# LPC15xx register map
File version: 0.7
CPU: CM3 r2p1, little endian, no MPU, no FPU, 3 interrupt priority bits
Registers are 32-bit, read-write, reset 0x0 unless marked. A register's access mark holds for its fields unless they carry their own. Offsets are from the block's base; [hi:lo] are bit positions; lines under a group give offsets from that group; {n}, {i} and the like mark numbered series.

## GINT0 — Group interrupt 0/1 (GINT0/1)
Base 0x400A8000
Same registers: GINT1 0x400AC000
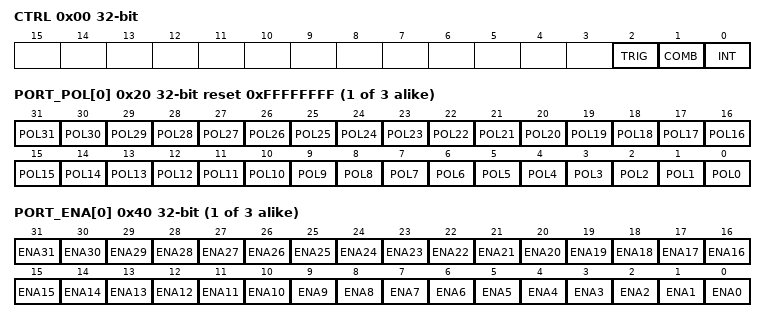
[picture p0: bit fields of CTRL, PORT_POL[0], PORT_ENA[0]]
0x00 CTRL — GPIO grouped interrupt control register
  [2] TRIG — Group interrupt trigger
    0=EDGE_TRIGGERED; 1=LEVEL_TRIGGERED
  [1] COMB — Combine enabled inputs for group interrupt
    0=OR_FUNCTIONALITY_A_ (OR functionality: A grouped interrupt is generated when any one of the enabled inputs is active (based on its programmed polarity).); 1=AND_FUNCTIONALITY_A (AND functionality: An interrupt is generated when all enabled bits are active (based on their programmed polarity).)
  [0] INT — Group interrupt status. This bit is cleared by writing a one to it. Writing zero has no effect.
    0=NO_INTERRUPT_REQUEST (No interrupt request is pending.); 1=INTERRUPT_REQUEST_IS (Interrupt request is active.)
{0x20+4i} PORT_POL[{i}] (i=0..2) reset 0xFFFFFFFF — GPIO grouped interrupt port 0 polarity register
  [n] POL{n} (n=0..31) — Configure pin polarity of port m pins for group interrupt. Bit n corresponds to pin PIOm_n of port m. 0 = the pin is active LOW. If the level on this pin is LOW, the pin contributes to the group interrupt. 1 = the pin is active HIGH. If the level on this pin is HIGH, the pin contributes to the group interrupt.
{0x40+4i} PORT_ENA[{i}] (i=0..2) — GPIO grouped interrupt port 0 enable register
  [n] ENA{n} (n=0..31) — Enable port 0 pin for group interrupt. Bit n corresponds to pin Pm_n of port m. 0 = the port 0 pin is disabled and does not contribute to the grouped interrupt. 1 = the port 0 pin is enabled and contributes to the grouped interrupt.

## RIT — Repetitive Interrupt Timer (RIT)
Base 0x400B4000
0x00 COMPVAL reset 0xFFFFFFFF — Compare value LSB register. Holds the 32 LSBs of the compare value.
  [31:0] RICOMP — Compare register. Holds the 32 LSBs of the compare value which is compared to the counter.
0x04 MASK — Mask LSB register. This register holds the 32 LSB s of the mask value. A 1 written to any bit will force a compare on the corresponding bit of the counter and compare register.
  [31:0] RIMASK — Mask register. This register holds the 32 LSBs of the mask value. A one written to any bit overrides the result of the comparison for the corresponding bit of the counter and compare register (causes the comparison of the register bits to be always true).
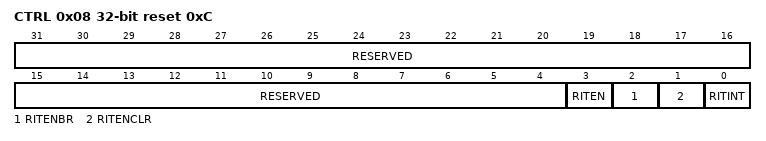
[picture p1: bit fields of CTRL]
0x08 CTRL reset 0xC — Control register.
  [31:4] RESERVED — Reserved, user software should not write ones to reserved bits. The value read from a reserved bit is not defined.
  [3] RITEN — Timer enable.
    1=TIMER_ENABLED (Timer enabled. This can be overruled by a debug halt if enabled in bit 2.); 0=TIMER_DISABLED
  [2] RITENBR — Timer enable for debug
    1=THE_TIMER_IS_HALTED (The timer is halted when the processor is halted for debugging.); 0=DEBUG_HAS_NO_EFFECT (Debug has no effect on the timer operation.)
  [1] RITENCLR — Timer enable clear
    1=THE_TIMER_WILL_BE_CL (The timer will be cleared to 0 whenever the counter value equals the masked compare value specified by the contents of COMPVAL/COMPVAL_H and MASK/MASK_H registers. This will occur on the same clock that sets the interrupt flag.); 0=THE_TIMER_WILL_NOT_B (The timer will not be cleared to 0.)
  [0] RITINT — Interrupt flag
    1=THIS_BIT_IS_SET_TO_1 (This bit is set to 1 by hardware whenever the counter value equals the masked compare value specified by the contents of RICOMPVAL and RIMASK registers. Writing a 1 to this bit will clear it to 0. Writing a 0 has no effect.); 0=THE_COUNTER_VALUE_DO (The counter value does not equal the masked compare value.)
0x0C COUNTER — Counter LSB register. 32 LSBs of the counter.
  [31:0] RICOUNTER — 32 LSBs of the up counter. Counts continuously unless RITEN bit in CTRL register is cleared or debug mode is entered (if enabled by the RITNEBR bit in RICTRL). Can be loaded to any value in software.
0x10 COMPVAL_H reset 0xFFFF — Compare value MSB register. Holds the 16 MSBs of the compare value.
  [15:0] RICOMP — Compare value MSB register. Holds the 16 MSBs of the compare value which is compared to the counter.
0x14 MASK_H — Mask MSB register. This register holds the 16 MSBs of the mask value. A 1 written to any bit will force a compare on the corresponding bit of the counter and compare register.
  [15:0] RIMASK — Mask register. This register holds the 16 MSBs of the mask value. A one written to any bit overrides the result of the comparison for the corresponding bit of the counter and compare register (causes the comparison of the register bits to be always true).
0x1C COUNTER_H — Counter MSB register. 16 MSBs of the counter.
  [15:0] RICOUNTER — 16 LSBs of the up counter. Counts continuously unless RITEN bit in RICTRL register is cleared or debug mode is entered (if enabled by the RITNEBR bit in RICTRL). Can be loaded to any value in software.

## FLASHCTRL — Flash controller
Base 0x400BC000
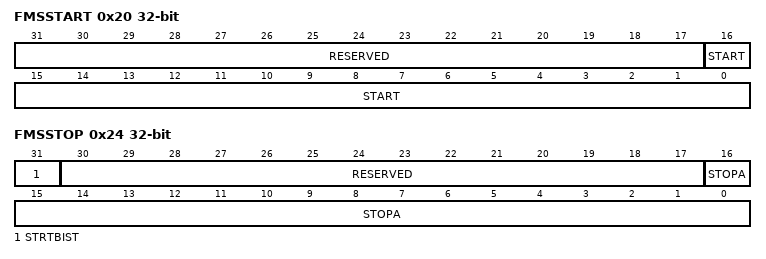
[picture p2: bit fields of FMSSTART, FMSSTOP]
0x20 FMSSTART — Signature start address register
  [31:17] RESERVED — Reserved, user software should not write ones to reserved bits. The value read from a reserved bit is not defined.
  [16:0] START — Signature generation start address (corresponds to AHB byte address bits[20:4]).
0x24 FMSSTOP — Signature stop-address register
  [31] STRTBIST — When this bit is written to 1, signature generation starts. At the end of signature generation, this bit is automatically cleared.
  [30:17] RESERVED — Reserved, user software should not write ones to reserved bits. The value read from a reserved bit is not defined.
  [16:0] STOPA — Stop address for signature generation (the word specified by STOPA is included in the address range). The address is in units of memory words, not bytes.
0x2C FMSW0 ro reset not defined — Signature word
  [31:0] SIG — 32-bit signature.
